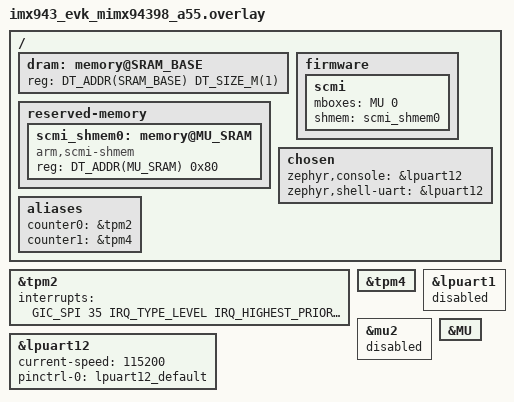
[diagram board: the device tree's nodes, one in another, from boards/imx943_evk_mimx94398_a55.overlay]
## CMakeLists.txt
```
cmake_minimum_required(VERSION 3.13.1)

find_package(Zephyr REQUIRED HINTS $ENV{ZEPHYR_BASE})
project(rt_latency)

if(CONFIG_BOARD_IMX8MM_EVK)
    set(BoardName "evkmimx8mm")
elseif(CONFIG_BOARD_IMX8MN_EVK)
    set(BoardName "evkmimx8mn")
elseif(CONFIG_BOARD_IMX8MP_EVK)
    set(BoardName "evkmimx8mp")
elseif(CONFIG_BOARD_IMX93_EVK)
    set(BoardName "mcimx93evk")
elseif(CONFIG_BOARD_IMX943_EVK)
    set(BoardName "imx943evk")
elseif(CONFIG_BOARD_IMX95_EVK_15X15)
    set(BoardName "imx95lp4xevk15")
elseif(CONFIG_BOARD_IMX95_EVK)
    set(BoardName "imx95lpd5evk19")
endif()

set(ProjDirPath ${CMAKE_CURRENT_SOURCE_DIR})
set(CommonPath "${ProjDirPath}/../../common")
set(CommonBoardPath "${ProjDirPath}/../../common/boards/${BoardName}")
set(AppPath "${ProjDirPath}/..")
set(ProjRootPath "${ProjDirPath}/../../")
set(RtosAbstractionLayerPath "${ProjRootPath}/../rtos-abstraction-layer/zephyr")
set(RtosAppsPath "${ProjRootPath}/../rtos-apps")

zephyr_include_directories(
	${AppPath}/common
	${AppPath}/zephyr/include
	${CommonPath}
	${CommonPath}/zephyr/boards
	${CommonBoardPath}
	${CommonPath}/libs/jailhouse
	${CommonPath}/libs/ctrl
	${CommonPath}/libs/gen_sw_mbox
	${ProjDirPath}
	)

set(MCUX_SDK_PROJECT_NAME app)

set(CMAKE_MODULE_PATH
    ${CommonPath}/libs/ctrl
    ${CommonPath}/libs/jailhouse
    ${CommonPath}/libs/gen_sw_mbox
    ${CommonPath}/libs/rpmsg
    ${RtosAbstractionLayerPath}
)

set(RTOS_ABSTRACTION_LAYER_TARGET ${MCUX_SDK_PROJECT_NAME})
include(rtos_abstraction_layer)

set(RTOS_APPS_TARGET ${MCUX_SDK_PROJECT_NAME})
include(${RtosAppsPath}/rtos_apps_log.cmake)
include(${RtosAppsPath}/rtos_apps_stats.cmake)

zephyr_compile_definitions(OS_ZEPHYR)

# Cortex-A55/A53 core maximum clock frequency
zephyr_compile_definitions_ifdef(CONFIG_BOARD_IMX8MM_EVK SDK_DEVICE_MAXIMUM_CPU_CLOCK_FREQUENCY=1800000000UL)
zephyr_compile_definitions_ifdef(CONFIG_BOARD_IMX8MN_EVK SDK_DEVICE_MAXIMUM_CPU_CLOCK_FREQUENCY=1600000000UL)
zephyr_compile_definitions_ifdef(CONFIG_BOARD_IMX8MP_EVK SDK_DEVICE_MAXIMUM_CPU_CLOCK_FREQUENCY=1800000000UL)
zephyr_compile_definitions_ifdef(CONFIG_BOARD_IMX93_EVK SDK_DEVICE_MAXIMUM_CPU_CLOCK_FREQUENCY=1700000000UL)

# include modules

include(lib_jailhouse)
include(lib_ctrl)

include(lib_rpmsg)
include(lib_gen_sw_mbox)

if(CONFIG_BOARD_IMX943_EVK)
target_sources(app PRIVATE
       ${CommonPath}/zephyr/boards/imx943evk/clock_init.c
)
endif()

target_sources(app PRIVATE main.c)
target_sources(app PRIVATE ../common/rt_latency.c)
```

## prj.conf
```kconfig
CONFIG_KERNEL_BIN_NAME="rt_latency"

CONFIG_MAX_XLAT_TABLES=20
CONFIG_STDOUT_CONSOLE=y
# enable to use thread names
CONFIG_THREAD_NAME=y
CONFIG_SCHED_CPU_MASK=y

CONFIG_COUNTER=y

CONFIG_RPMSGLITE=y
CONFIG_RPMSGLITE_QUEUE=y
CONFIG_RPMSGLITE_NS=y

# Logging subsystem
CONFIG_LOG=y
CONFIG_LOG_PRINTK=y
CONFIG_LOG_BUFFER_SIZE=65536
CONFIG_LOG_PROCESS_THREAD_CUSTOM_PRIORITY=y
# Use K_LOWEST_APPLICATION_THREAD_PRIO -1 priority as CPU load is using K_LOWEST_APPLICATION_THREAD_PRIO
CONFIG_LOG_PROCESS_THREAD_PRIORITY=13
CONFIG_HEAP_MEM_POOL_SIZE=16384
CONFIG_DYNAMIC_INTERRUPTS=y
CONFIG_EVENTS=y
CONFIG_ASSERT=y

CONFIG_KERNEL_DIRECT_MAP=y
```

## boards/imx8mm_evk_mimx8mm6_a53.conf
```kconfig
# Enable Zephyr's GPT Counter driver
CONFIG_COUNTER_MCUX_GPT=y
```

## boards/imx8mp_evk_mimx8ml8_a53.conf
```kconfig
# Map GPT memory regions and include mcux sdk driver
CONFIG_HAS_MCUX_GPT=y
# Enable Zephyr's GPT Counter driver
CONFIG_COUNTER_MCUX_GPT=y
```

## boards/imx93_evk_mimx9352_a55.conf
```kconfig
CONFIG_COUNTER_MCUX_TPM=y
```

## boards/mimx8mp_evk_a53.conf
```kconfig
CONFIG_COUNTER=y
CONFIG_COUNTER_MCUX_GPT=y
```

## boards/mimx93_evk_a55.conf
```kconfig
CONFIG_COUNTER_MCUX_TPM=y
CONFIG_HAS_MCUX_TPM=y
```

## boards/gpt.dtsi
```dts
/*
 * Copyright 2022-2023, 2025 NXP
 *
 * SPDX-License-Identifier: BSD-3-Clause
 */

#define IRQ_HIGHEST_PRIORITY	0

/ {
	aliases {
		counter0 = &gpt1;
		counter1 = &gpt2;
	};
};

&gpt1 {
	interrupts = <GIC_SPI 55 IRQ_TYPE_LEVEL
		IRQ_HIGHEST_PRIORITY>;
	status = "okay";
};

&gpt2 {
	status = "okay";
};
```

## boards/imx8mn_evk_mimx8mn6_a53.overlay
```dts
/*
 * Copyright 2022, 2024-2025 NXP
 *
 * SPDX-License-Identifier: BSD-3-Clause
 */

#include "gpt.dtsi"

&rdc {
	status = "disabled";
};

&enet {
	status = "disabled";
};

&enet_mac {
	status = "disabled";
};

&enet_mdio {
	status = "disabled";
};

&i2c3 {
	status = "disabled";
};

&gpio1 {
	status = "disabled";
};
```

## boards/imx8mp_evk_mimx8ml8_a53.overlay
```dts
/*
 * Copyright 2021-2022, 2024-2025 NXP
 *
 * SPDX-License-Identifier: BSD-3-Clause
 */

#include "gpt.dtsi"

&rdc {
	status = "disabled";
};

&enet {
	status = "disabled";
};

&enet_mac {
	status = "disabled";
};

&enet_mdio {
	status = "disabled";
};

&i2c3 {
	status = "disabled";
};

&gpio1 {
	status = "disabled";
};

&flexcan1 {
	status = "disabled";
};
```

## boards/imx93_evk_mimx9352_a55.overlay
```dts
/*
 * Copyright 2023-2025 NXP
 *
 * SPDX-License-Identifier: BSD-3-Clause
 */

#define IRQ_HIGHEST_PRIORITY	0

/ {
	aliases {
		counter0 = &tpm2;
		counter1 = &tpm4;
	};
};

&tpm2 {
	interrupts = <GIC_SPI 37 IRQ_TYPE_LEVEL
		IRQ_HIGHEST_PRIORITY>;
	status = "okay";
};

&tpm4 {
	status = "okay";
};

&enet {
	status = "disabled";
};

&enet_mac {
	status = "disabled";
};

&enet_mdio {
	status = "disabled";
};

&lpi2c2 {
	status = "disabled";
};
```

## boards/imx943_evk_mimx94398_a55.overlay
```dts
/*
 * Copyright 2024-2025 NXP
 *
 * SPDX-License-Identifier: BSD-3-Clause
 */

#define IRQ_HIGHEST_PRIORITY	0

#define SRAM_BASE	f0000000
#define MU		mu3
#define MU_SRAM		445d1000

/delete-node/ &dram;
/delete-node/ &scmi_shmem0;

/ {
	dram: memory@SRAM_BASE {
		reg = <DT_ADDR(SRAM_BASE) DT_SIZE_M(1)>;
	};

	reserved-memory {
		#address-cells = <1>;
		#size-cells = <1>;

		scmi_shmem0: memory@MU_SRAM {
			compatible = "arm,scmi-shmem";
			reg = <DT_ADDR(MU_SRAM) 0x80>;
		};
	};

	firmware {
		scmi {
			mboxes = <&MU 0>;
			shmem = <&scmi_shmem0>;
		};
	};

	chosen {
		zephyr,console = &lpuart12;
		zephyr,shell-uart = &lpuart12;
	};

	aliases {
		counter0 = &tpm2;
		counter1 = &tpm4;
	};
};

&tpm2 {
	interrupts = <GIC_SPI 35 IRQ_TYPE_LEVEL
		IRQ_HIGHEST_PRIORITY>;
	status = "okay";
};

&tpm4 {
	status = "okay";
};

&lpuart1 {
	status = "disabled";
};

&lpuart12 {
	status = "okay";
	current-speed = <115200>;
	pinctrl-0 = <&lpuart12_default>;
	pinctrl-names = "default";
};

&mu2 {
	status = "disabled";
};

&MU {
	status = "okay";
};
```

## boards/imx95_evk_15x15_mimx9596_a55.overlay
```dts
/*
 * Copyright 2025 NXP
 *
 * SPDX-License-Identifier: BSD-3-Clause
 */

#define IRQ_HIGHEST_PRIORITY	0

#define SRAM_BASE	f0000000
#define MU		mu3
#define MU_SRAM		445d1000

/delete-node/ &dram;
/delete-node/ &scmi_shmem0;

/ {
	dram: memory@SRAM_BASE {
		reg = <DT_ADDR(SRAM_BASE) DT_SIZE_M(1)>;
	};

	reserved-memory {
		#address-cells = <1>;
		#size-cells = <1>;

		scmi_shmem0: memory@MU_SRAM {
			compatible = "arm,scmi-shmem";
			reg = <DT_ADDR(MU_SRAM) 0x80>;
		};
	};

	firmware {
		scmi {
			mboxes = <&MU 0>;
			shmem = <&scmi_shmem0>;
		};
	};

	chosen {
		zephyr,console = &lpuart3;
		zephyr,shell-uart = &lpuart3;
	};

	aliases {
		counter0 = &tpm2;
		counter1 = &tpm4;
	};
};

&tpm2 {
	interrupts = <GIC_SPI 30 IRQ_TYPE_LEVEL
		IRQ_HIGHEST_PRIORITY>;
	status = "okay";
};

&tpm4 {
	status = "okay";
};

&lpuart1 {
	status = "disabled";
};

&lpuart3 {
	status = "okay";
	current-speed = <115200>;
	pinctrl-0 = <&lpuart3_default>;
	pinctrl-names = "default";
};

&mu2 {
	status = "disabled";
};

&MU {
	status = "okay";
};
```

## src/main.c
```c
/*
 * Copyright 2021 NXP.
 *
 * SPDX-License-Identifier: BSD-3-Clause
 */

#include <ztest.h>
#include <zephyr.h>
#include <kernel.h>
#include <device.h>
#include <sys/printk.h>

#include "rt_latency.h"
#include "rt_tc_setup.h"

#define STACK_SIZE (640 + CONFIG_TEST_EXTRA_STACKSIZE)

K_THREAD_STACK_DEFINE(gpt_stack, STACK_SIZE);

#ifdef WITH_CPU_LOAD
K_THREAD_STACK_DEFINE(cpu_load_stack, STACK_SIZE);
#endif

#ifdef WITH_INVD_CACHE
K_THREAD_STACK_DEFINE(cache_inval_stack, STACK_SIZE);
#endif

#ifndef SILENT_TESTING
K_THREAD_STACK_DEFINE(print_stack, STACK_SIZE);
#endif

#define INST_DT_COMPAT_LABEL(n, compat) DT_LABEL(DT_INST(n, compat)),
/* Generate a list of LABELs for all instances of the "compat" */
#define LABELS_FOR_DT_COMPAT(compat) \
	COND_CODE_1(DT_HAS_COMPAT_STATUS_OKAY(compat), \
		   (UTIL_LISTIFY(DT_NUM_INST_STATUS_OKAY(compat), \
				 INST_DT_COMPAT_LABEL, compat)), ())

static const char * const devices[] = {
	LABELS_FOR_DT_COMPAT(nxp_imx_gpt)
};

void gpt_latency_test(void *p1, void *p2, void *p3)
{
	const struct device *dev = p1;
	struct rt_latency_ctx *ctx = p2;
	int ret;

	k_object_access_grant(dev, k_current_get());

	ret = rt_latency_test(ctx);
	if (ret)
	{
		printk("test failed!\n");
		k_thread_suspend(k_current_get());
	}

	k_usleep(2000);
	k_thread_abort(k_current_get());
}

#ifdef WITH_CPU_LOAD
void cpu_load_func(void *p1, void *p2, void *p3)
{
	struct rt_latency_ctx *ctx = p2;

	cpu_load(ctx);
}
#endif

#ifdef WITH_INVD_CACHE
void cache_inval_func(void *p1, void *p2, void *p3)
{
	cache_inval();
}
#endif

void print_stats_func(void *p1, void *p2, void *p3)
{
	struct rt_latency_ctx *ctx = p2;

	print_stats(ctx);
}

void test_main(void)
{
	const struct device *gpt_dev;
	const struct device *irq_load_dev;
	struct k_thread gpt_thread;
#ifdef WITH_CPU_LOAD
	struct k_thread cpu_load_thread;
#endif
#ifdef WITH_INVD_CACHE
	struct k_thread cache_inval_thread;
#endif
#ifndef SILENT_TESTING
	struct k_thread print_thread;
#endif

	static struct rt_latency_ctx rt_ctx;
	void *p3 = NULL;
	int ret;

	/* Initialize test case load conditions based on test case ID */
	rt_ctx.tc_load = 0;
#ifdef WITH_IRQ_LOAD
	rt_ctx.tc_load |= RT_LATENCY_WITH_IRQ_LOAD;
#endif
#ifdef WITH_CPU_LOAD
	rt_ctx.tc_load |= RT_LATENCY_WITH_CPU_LOAD;
#endif
#ifdef WITH_CPU_LOAD_SEM
	rt_ctx.tc_load |= RT_LATENCY_WITH_CPU_LOAD_SEM;
#endif

	/* Give required clocks some time to stabilize. In particular, nRF SoCs
	 * need such delay for the Xtal LF clock source to start and for this
	 * test to use the correct timing.
	 */
	k_busy_wait(USEC_PER_MSEC * 300);

	/* Create GPT threads with Highest Priority*/
	gpt_dev = device_get_binding(devices[0]);
	if(!gpt_dev)
		printk("Unable to get counter device\n");

	/* Use the second GPT Counter to create irq load with lower priority */
	irq_load_dev = device_get_binding(devices[1]);
	if(!irq_load_dev)
		printk("Unable to get counter device\n");
	p3 = (void *)irq_load_dev;

	ret = rt_latency_init(gpt_dev, p3, &rt_ctx);
	if (ret)
		printk("Initialization failed!\n");

	k_thread_create(&gpt_thread, gpt_stack, STACK_SIZE,
		gpt_latency_test, (void *)gpt_dev, &rt_ctx, p3,
		K_HIGHEST_THREAD_PRIO, 0, K_FOREVER);

	k_busy_wait(USEC_PER_MSEC * 300);
#ifdef THREAD_CPU_BINDING
	k_thread_cpu_mask_clear(&gpt_thread);
	k_thread_cpu_mask_enable(&gpt_thread, GPT_CPU_BINDING);
#endif

#ifndef SILENT_TESTING
	/* Print Thread */
	k_thread_create(&print_thread, print_stack, STACK_SIZE,
			print_stats_func, NULL, &rt_ctx, NULL,
			K_LOWEST_APPLICATION_THREAD_PRIO - 2, 0, K_FOREVER);
#ifdef THREAD_CPU_BINDING
	k_thread_cpu_mask_clear(&print_thread);
	k_thread_cpu_mask_enable(&print_thread, PRINT_CPU_BINDING);
#endif
	k_thread_start(&print_thread);
#endif

	/* CPU Load Thread */
#ifdef WITH_CPU_LOAD
	k_thread_create(&cpu_load_thread, cpu_load_stack, STACK_SIZE,
			cpu_load_func, NULL, &rt_ctx, NULL,
			K_LOWEST_APPLICATION_THREAD_PRIO, 0, K_FOREVER);
#ifdef THREAD_CPU_BINDING
	k_thread_cpu_mask_clear(&cpu_load_thread);
	k_thread_cpu_mask_enable(&cpu_load_thread, CPU_LOAD_CPU_BINDING);
#endif
	k_thread_start(&cpu_load_thread);
#endif

	/* Cache Invalidate Thread */
#ifdef WITH_INVD_CACHE
	k_thread_create(&cache_inval_thread, cache_inval_stack, STACK_SIZE,
			cache_inval_func, NULL, NULL, NULL,
			K_LOWEST_APPLICATION_THREAD_PRIO - 1, 0, K_FOREVER);
#ifdef THREAD_CPU_BINDING
	k_thread_cpu_mask_clear(&cache_inval_thread);
	k_thread_cpu_mask_enable(&cache_inval_thread, CPU_LOAD_CPU_BINDING);
#endif
	k_thread_start(&cache_inval_thread);
#endif

	/* Start GPT Threads */
	k_thread_start(&gpt_thread);

	k_thread_join(&gpt_thread, K_FOREVER);

#ifndef SILENT_TESTING
	k_thread_abort(&print_thread);
#endif
}
```

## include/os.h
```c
/*
 * Copyright 2021 NXP.
 *
 * SPDX-License-Identifier: BSD-3-Clause
 */

#define OS_ZEPHYR

#include "os_zephyr.h"
```

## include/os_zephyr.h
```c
/*
 * Copyright 2021 NXP.
 *
 * SPDX-License-Identifier: BSD-3-Clause
 */

#ifndef _OS_ZEPHYR_H_
#define _OS_ZEPHYR_H_

#include <drivers/counter.h>
#include <ztest.h>
#include <zephyr.h>
#include <kernel.h>
#include <sys/printk.h>
#include <cache.h>

#define os_counter_get_top_value(dev)	counter_get_top_value(dev)

#define os_counter_is_counting_up(dev)	counter_is_counting_up(dev)

#define os_counter_ticks_to_ns(dev, ticks) 	counter_ticks_to_ns(dev, ticks)

#define os_counter_get_value(dev, now)	counter_get_value(dev, now)

#define os_counter_set_channel_alarm(dev, channel, h_alarm_cfg)		\
		counter_set_channel_alarm(dev, channel, h_alarm_cfg)

#define os_counter_start(dev)	counter_start(dev)

#define os_counter_stop(dev)	counter_stop(dev)

#define os_sem_init(sem, init_count, limit)	\
		k_sem_init(sem, init_count, limit)

#define os_sem_reset(sem)	k_sem_reset(sem)

#define os_sem_give(sem)	k_sem_give(sem)

#define os_sem_take(sem, timeout)	k_sem_take(sem, timeout)

#define os_thread_resume(handler)	k_thread_resume(handler);

#define os_thread_suspend(h_thread)	k_thread_suspend(h_thread)

#define os_thread_abort(h_thread)	k_thread_abort(h_thread)

#define os_assert_true(cond, msg, ...) zassert_true(cond, msg, ##__VA_ARGS__)

#define os_assert_equal(a, b, msg, ...) zassert_equal(a, b, msg, ##__VA_ARGS__)

#define os_usleep(us)	k_usleep(us)

#define os_busy_wait(us)	k_busy_wait(us)

#define printf(...)	printk(__VA_ARGS__)

#define os_invd_dcache_all() sys_cache_data_all(K_CACHE_INVD)

#define os_invd_icache_all() __asm volatile ("IC IALLUIS")

#endif /* _OS_ZEPHYR_H_ */
```
